# YTM32B1HA0 register map
Vendor: YTMicro; File version: 1.0
CPU: little endian, MPU, FPU, 2 interrupt priority bits
Registers are 32-bit, read-write, reset 0x0 unless marked. A register's access mark holds for its fields unless they carry their own. Offsets are from the block's base; [hi:lo] are bit positions; {n}, {i} and the like mark numbered series; 'fields as' and 'values as' point back to an identical list.

## ADC0
Base 0x40100000; register names take the prefix ADC0_
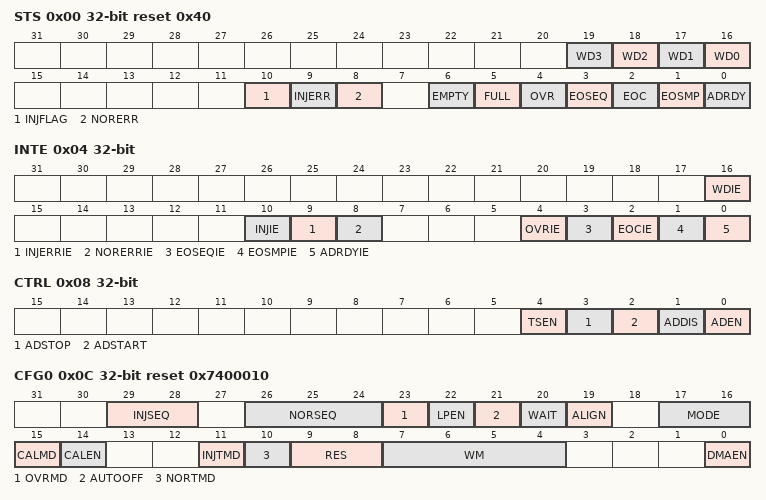
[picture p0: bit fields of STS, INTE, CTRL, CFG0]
0x00 STS reset 0x40
  [n+16] WD{n} (n=0..3) — This bit is set by hardware when the converted voltage crosses the values defined in the WD{n}TH register. It is cleared by software writing 1 to it.
    0=No watchdog event occurred (or the flag event was already acknowledged and cleared by software); 1=Watchdog event occurred
  [10] INJFLAG — This bit is set by hardware when a valid inject trigger is detected. It is cleared by software writing 1 to it.
  [9] INJERR — This bit is set by hardware when inject trigger error occurs. Inject trigger error occurs when the inject triggered conversion is in progress and a new inject trigger comes. Besides, Inject trigger error occurs when a valid inject trigger comes and the ADC module is in off state or start-up state. Inject trigger error means inject trigger error missing. It is cleared by software writing 1 to it.
    0=Indicate inject trigger not missing; 1=Indicate inject trigger missing
  [8] NORERR — This bit is set by hardware when normal trigger error occurs. Normal trigger error occurs when the normal triggered conversion is in progress and a new normal trigger comes. Besides, normal trigger error occurs when a valid normal trigger comes and the ADC module is in off state or start-up state. Inject trigger error means inject trigger error missing. It is cleared by software writing 1 to it.
    values as INJERR
  [6] EMPTY ro — This bit is set by hardware when the FIFO is empty. It is cleared by hardware when FIFO is not empty.
    0=FIFO is not empty; 1=FIFO is empty
  [5] FULL ro — This bit is set by hardware when the FIFO is full. It is cleared by hardware when FIFO is not full.
    0=FIFO is not full; 1=FIFO is full
  [4] OVR — This bit is set by hardware when an overrun occurs, meaning that a new conversion has completed while the FULL flag was already set. It is cleared by software writing 1 to it.
    0=No overrun occurred (or the flag event was already acknowledged and cleared by software); 1=Overrun has occurred
  [3] EOSEQ — This bit is set by hardware at the end of the conversion of a sequence. It is cleared by software writing 1 to it.
    0=Conversion sequence not complete (or the flag event was already acknowledged and cleared by software); 1=Conversion sequence complete
  [2] EOC — This bit is set by hardware at the end of each conversion of a channel when a new data result is available in the FIFO register. It is cleared by software writing 1 to it or by reading the FIFO register.
    0=Channel conversion not complete (or the flag event was already acknowledged and cleared by software); 1=Channel conversion complete
  [1] EOSMP — This bit is set by hardware during the conversion at the end of the sampling phase.
    0=Not at the end of the sampling phase (or the flag event was already acknowledged and cleared by software); 1=End of sampling phase reached
  [0] ADRDY — This bit is set by hardware after the ADC has been enabled (ADEN=1) and when the ADC reaches a state where it is ready to accept conversion requests. It is cleared by software writing 1 to it.
    0=ADC not yet ready to start conversion (or the flag event was already acknowledged and cleared by software); 1=ADC is ready to start conversion
0x04 INTE
  [16] WDIE — This bit is set and cleared by software to enable/disable the analog watchdog interrupt.
    0=Watchdog interrupt disabled; 1=Watchdog interrupt enabled. An interrupt is generated when the WD bit is set.
  [10] INJIE — Inject interrupt enabled/disabled.
    0=Inject interrupt disabled; 1=Inject interrupt enabled
  [9] INJERRIE — Inject error interrupt enabled/disabled.
    0=Inject error interrupt disabled; 1=Inject error interrupt enabled
  [8] NORERRIE — Normal error interrupt enabled/disabled.
    0=Normal error interrupt disabled; 1=Normal error interrupt enabled
  [4] OVRIE — This bit is set and cleared by software to enable/disable the overrun interrupt.
    0=Overrun interrupt disabled; 1=Overrun interrupt enabled. An interrupt is generated when the OVR bit is set.
  [3] EOSEQIE — This bit is set and cleared by software to enable/disable the end of sequence of conversions interrupt.
    0=EOSEQ interrupt disabled; 1=EOSEQ interrupt enabled. An interrupt is generated when the EOSEQ bit is set.
  [2] EOCIE — This bit is set and cleared by software to enable/disable the end of conversion interrupt.
    0=EOC interrupt disabled; 1=EOC interrupt enabled. An interrupt is generated when the EOC bit is set.
  [1] EOSMPIE — This bit is set and cleared by software to enable/disable the end of the sampling phase interrupt.
    0=EOSMP interrupt disabled; 1=EOSMP interrupt enabled. An interrupt is generated when the EOSMP bit is set.
  [0] ADRDYIE — This bit is set and cleared by software to enable/disable the ADC Ready interrupt.
    0=ADRDY interrupt disabled; 1=ADRDY interrupt enabled. An interrupt is generated when the ADRDY bit is set.
0x08 CTRL
  [4] TSEN — This bit is to enable/disable internal Tempsenser. Only ADC0 support.
    0=Tempsenser is disabled; 1=Tempsenser is enabled
  [3] ADSTOP — This bit is set by software to stop and discard an ongoing conversion (ADSTOP Command). It is cleared by hardware when the conversion is effectively discarded and the ADC is ready to accept a new start conversion command. Software is allowed to set ADSTOP only when ADSTART=1 and ADDIS=0 (ADC is enabled and may be converting and there is no pending request to disable the ADC).
    0=No ADC stop conversion command ongoing; 1=Write 1 to stop the ADC. Read 1 means that an ADSTOP command is in progress.
  [2] ADSTART — This bit is set by software to start ADC conversion. Depending on the TRIGMD configuration bits, conversion either starts immediately (software trigger configuration) or once a hardware trigger event occurs (hardware trigger configuration). Software is allowed to set ADSTART only when ADEN=1 and ADDIS=0 (ADC is enabled and there is no pending request to disable the ADC).
    0=No ADC conversion is ongoing; 1=Write 1 to start the ADC. Read 1 means that the ADC is operating and may be converting.
  [1] ADDIS — This bit is set by software to disable the ADC (ADDIS command) and put it into power-down state (OFF state). It is cleared by hardware once the ADC is effectively disabled (ADEN is also cleared by hardware at this time).
    0=No ADDIS command ongoing; 1=Write 1 to disable the ADC. Read 1 means that an ADDIS command is in progress.
  [0] ADEN — This bit is set by software to enable the ADC. The ADC will be effectively ready to operate once the ADRDY flag has been set. It is cleared by hardware when the ADC is disabled, after the execution of the ADDIS command.
    0=ADC is disabled (OFF state); 1=Write 1 to enable the ADC. Read 1 means that the ADC is enabled.
0x0C CFG0 reset 0x7400010
  [29:28] INJSEQ — These bits define the length of sequence. The sequence length is SEQLEN+1. For example, INJSEQ=3 means sequence length is 4; INJSEQ=0 means sequence length is 1.
  [26:24] NORSEQ — These bits define the length of sequence. The sequence length is NORSEQ+1. For example, NORSEQ=7 means sequence length is 8; SEQLEN=0 means sequence length is 1.
  [23] OVRMD — This bit is set and cleared by software and configure the way data overruns.
    0=FIFO register is preserved with the old data when an overrun is detected; 1=The last data is overwritten with the conversion result when an overrun is detected
  [22] LPEN — Keep working enabled/disabled in low power mode.
    0=Keep working enabled in low power mode; 1=Keep working disabled in low power mode
  [21] AUTOOFF — This bit is set and cleared by software to enable/disable auto-off mode.
    0=Auto-off mode disabled; 1=Auto-off mode enabled
  [20] WAIT — This bit is set and cleared by software to enable/disable wait mode.
    0=Wait mode off; 1=Wait mode on
  [19] ALIGN — Data write/left aligned when read FIFO.
    0=Write aligned; 1=Left aligned
  [17:16] MODE — Work mode selection.
    0=Single mode; 1=Continuous mode; 2=Discontinuous mode
  [15] CALMD
    0=The conversion result will not be calibrated automatically; 1=The conversion result will be calibrated automatically
  [14] CALEN
    0=Calibration disabled; 1=Calibration enabled
  [11] INJTMD
    0=Not select hardware trigger as the trigger source; 1=Select hardware trigger as the trigger source
  [10] NORTMD
    0=Select software trigger as the trigger source; 1=Select hardware trigger as the trigger source
  [9:8] RES — These bits are written by software to select the resolution of the conversion.
    0=12-bit resolution; 1=10-bit resolution; 2=8-bit resolution; 3=6-bit resolution
  [7:4] WM — When conversion data number is more than WM value and DMA enabled, trigger a DMA request.
  [0] DMAEN — This bit is set and cleared by software to enable the generation of DMA requests. This allows to use the DMA controller to manage conversion data automatically.
    0=DMA disable; 1=DMA enable
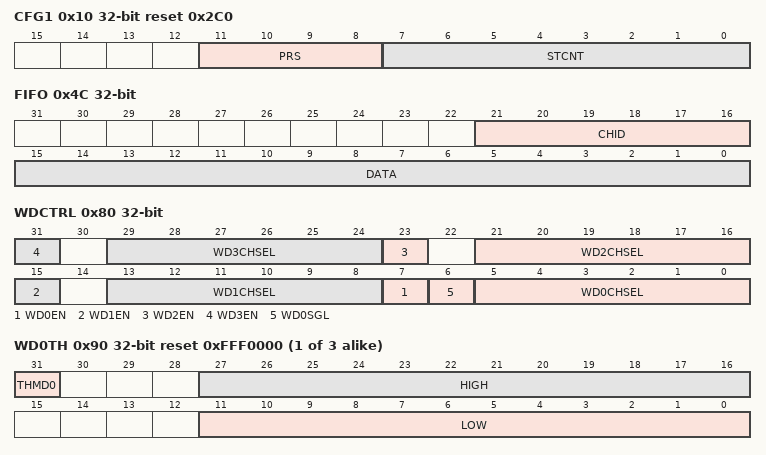
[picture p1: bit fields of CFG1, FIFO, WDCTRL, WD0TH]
0x10 CFG1 reset 0x2C0
  [11:8] PRS, [7:0] STCNT
0x14 SMP reset 0x2
  [7:0] SMP
{0x2C+i} CHSEL{i} 8-bit (i=0..7)
  [5:0] CHSEL — These bits are configured by software to select the conversion channel.
{0x34+i} INJCH{i} 8-bit (i=0..3)
  [5:0] INJCH — These bits are configured by software to select the inject conversion channel.
0x4C FIFO
  [21:16] CHID ro — These bits indicate the channel identification that corresponds with the conversion data.
  [15:0] DATA ro — Converted data
0x54 TSC
  [11:0] COEFF — Temperature sensor coefficient value.
0x60 CAL
  [11:0] OFFSET — Signed Offset value after calibration. Negative values are in complement format.
0x80 WDCTRL
  [8n+7] WD{n}EN (n=0..3) — This bit is set and cleared by software to enable/disable watchdog.
    0=Watchdog {n} is disabled; 1=Watchdog {n} is enabled
  [8n+5:8n] WD{n}CHSEL (n=0..3) — These bits are set and cleared by software. They select the input channel to be guarded by the watchdog.
  [6] WD0SGL — This bit is set and cleared by software to apply the watchdog on the channel identified by the WDCHSEL or all channels.
    0=Watchdog 0 enabled on all channels; 1=Watchdog 0 enabled on a single channel
{0x90+4i} WD{i}TH reset 0xFFF0000 (i=0..2)
  [31] THMD{i} — This bit is set and cleared by software to select the watchdog {i} threshold effective mode.
    0=Watchdog {i} output validly when the converted voltage is outside the threshold defined by HIGH and LOW; 1=Watchdog {i} output validly when the converted voltage is inside the threshold defined by HIGH and LOW
  [27:16] HIGH — These bits are written by software to define the higher threshold for the watchdog {i}.
  [11:0] LOW — These bits are written by software to define the lower threshold for the watchdog {i}.
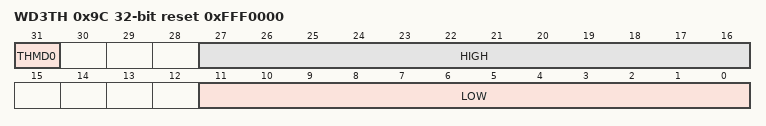
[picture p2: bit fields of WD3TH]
0x9C WD3TH reset 0xFFF0000
  [31] THMD0 — This bit is set and cleared by software to select the watchdog 3 threshold effective mode.
    0=Watchdog 3 output validly when the converted voltage is outside the threshold defined by HIGH and LOW; 1=Watchdog 3 output validly when the converted voltage is inside the threshold defined by HIGH and LOW
  [27:16] HIGH — These bits are written by software to define the higher threshold for the watchdog 3.
  [11:0] LOW — These bits are written by software to define the lower threshold for the watchdog 3.
{0xB0+4i} INJ{i} (i=0..3)
  [11:0] DATA ro — Inject conversion result {i}.

## ADC1
Base 0x40104000; register names take the prefix ADC1_
Registers as ADC0; these are added or differ:
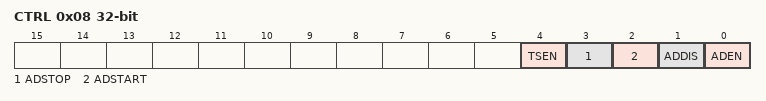
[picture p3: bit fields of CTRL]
0x08 CTRL
  fields as ADC0.CTRL
